# R7KA8T2AD register map
Vendor: Renesas Electronics Corporation; Series: RA8; File version: 1.10.02
CPU: CM85 r0p2, little endian, MPU, FPU, VTOR, 4 interrupt priority bits, 96 interrupts
Registers are 32-bit, read-write, reset 0x0 unless marked. A register's access mark holds for its fields unless they carry their own. Offsets are from the block's base; [hi:lo] are bit positions; 'fields as' and 'values as' point back to an identical list.

## IWDT_NS — Independent Watchdog Timer
Base 0x50202200
0x00 IWDTRR 8-bit reset 0xFF — IWDT Refresh Register
  [7:0] REFRESH
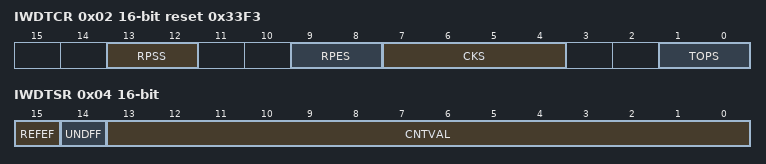
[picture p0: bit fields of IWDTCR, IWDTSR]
0x02 IWDTCR 16-bit reset 0x33F3 — IWDT Control Register
  [13:12] RPSS — Window Start Position Select
    0=25%; 1=50%; 2=75%; 3=100% (No window start position setting)
  [9:8] RPES — Window End Position Select
    0=75%; 1=50%; 2=25%; 3=0% (No window end position setting)
  [7:4] CKS — Clock Division Ratio Select
  [1:0] TOPS — Timeout Period Select
    0=128 cycles (0x007F); 1=512 cycles (0x01FF); 2=1024 cycles (0x03FF); 3=2048 cycles (0x07FF)
0x04 IWDTSR 16-bit — IWDT Status Register
  [15] REFEF — Refresh Error Flag
    0=No refresh error occurred; 1=Refresh error occurred
  [14] UNDFF — Underflow Flag
    0=No underflow occurred; 1=Underflow occurred
  [13:0] CNTVAL ro — Down-Counter Value
0x06 IWDTRCR 8-bit reset 0x80 — IWDT Reset Control Register
  [7] RSTIRQS — Reset Interrupt Request Select
    0=Enable non-maskable interrupt requests or interrupt request output; 1=Enable reset output
0x08 IWDTCSTPR 8-bit reset 0x80 — IWDT Count Stop Control Register
  [7] SLCSTP — CPU Sleep-Mode Count Stop Select
    0=Disable count stop; 1=Stop the counter when the primary CPU enters CPU Sleep mode or CPU Deep Sleep mode, and when the MCU enters Software Standby mode or Deep Software Standby mode 1

## CAC_NS — Clock Frequency Accuracy Measurement Circuit
Base 0x50202400
0x00 CACR0 8-bit — CAC Control Register 0
  [0] CFME — Clock Frequency Measurement Enable
    0=Disable; 1=Enable
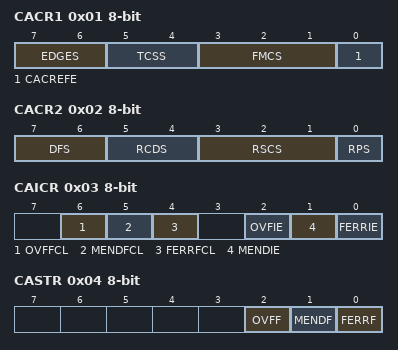
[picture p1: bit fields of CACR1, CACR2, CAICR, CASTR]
0x01 CACR1 8-bit — CAC Control Register 1
  [7:6] EDGES — Valid Edge Select
    0=Rising edge; 1=Falling edge; 2=Both rising and falling edges; 3=Setting prohibited
  [5:4] TCSS — Timer Count Clock Source Select
    0=No division; 1=x 1/4 clock; 2=x 1/8 clock; 3=x 1/32 clock
  [3:1] FMCS — Measurement Target Clock Select
    0=Main clock oscillator (CACMCLK); 1=Sub-clock oscillator (CACSCLK); 2=HOCO clock (CACHCLK); 3=MOCO clock (CACMOCLK); 4=LOCO clock (CACLCLK); 5=Peripheral module clock B (PCLKB); 6=Setting prohibited; 7=Setting prohibited
  [0] CACREFE — CACREF Pin Input Enable
    0=Disable; 1=Enable
0x02 CACR2 8-bit — CAC Control Register 2
  [7:6] DFS — Digital Filter Select
    0=Disable digital filtering; 1=Use sampling clock for the digital filter as the frequency measuring clock; 2=Use sampling clock for the digital filter as the frequency measuring clock divided by 4; 3=Use sampling clock for the digital filter as the frequency measuring clock divided by 16
  [5:4] RCDS — Measurement Reference Clock Frequency Division Ratio Select
    0=x 1/32 clock; 1=x 1/128 clock; 2=x 1/1024 clock; 3=x 1/8192 clock
  [3:1] RSCS — Measurement Reference Clock Select
    values as CACR1.FMCS
  [0] RPS — Reference Signal Select
    0=CACREF pin input; 1=Internal clock (internally generated signal)
0x03 CAICR 8-bit — CAC Interrupt Control Register
  [6] OVFFCL wo — OVFF Clear
    0=No effect; 1=The CASTR.OVFF flag is cleared
  [5] MENDFCL wo — MENDF Clear
    0=No effect; 1=The CASTR.MENDF flag is cleared
  [4] FERRFCL wo — FERRF Clear
    0=No effect; 1=The CASTR.FERRF flag is cleared
  [2] OVFIE — Overflow Interrupt Request Enable
    0=Disable; 1=Enable
  [1] MENDIE — Measurement End Interrupt Request Enable
    0=Disable; 1=Enable
  [0] FERRIE — Frequency Error Interrupt Request Enable
    0=Disable; 1=Enable
0x04 CASTR 8-bit ro — CAC Status Register
  [2] OVFF — Overflow Flag
    0=Counter has not overflowed; 1=Counter overflowed
  [1] MENDF — Measurement End Flag
    0=Measurement is in progress; 1=Measurement ended
  [0] FERRF — Frequency Error Flag
    0=Clock frequency is within the allowable range; 1=Clock frequency has deviated beyond the allowable range (frequency error)
0x06 CAULVR 16-bit — CAC Upper-Limit Value Setting Register
0x08 CALLVR 16-bit — CAC Lower-Limit Value Setting Register
0x0A CACNTBR 16-bit ro — CAC Counter Buffer Register
